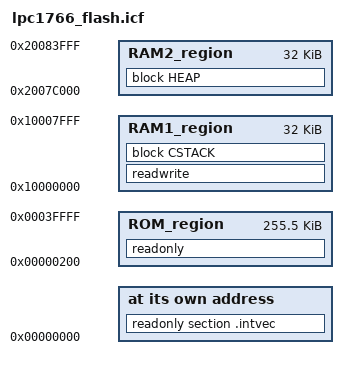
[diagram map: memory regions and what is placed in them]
/*###ICF### Section handled by ICF editor, don't touch! ****/
/*-Editor annotation file-*/
/* IcfEditorFile="$TOOLKIT_DIR$\config\ide\IcfEditor\cortex_v1_0.xml" */
/*-Specials-*/
define symbol __ICFEDIT_intvec_start__ = 0x00000000;
/*-Memory Regions-*/
define symbol __ICFEDIT_region_ROM_start__ = 0x00000200;
define symbol __ICFEDIT_region_ROM_end__   = 0x0003FFFF;
define symbol __ICFEDIT_region_RAM_start__ = 0x10000000;
define symbol __ICFEDIT_region_RAM_end__   = 0x10007FFF;
/*-Sizes-*/
define symbol __ICFEDIT_size_cstack__ = 0x400;
define symbol __ICFEDIT_size_heap__   = 0x8000;
/**** End of ICF editor section. ###ICF###*/

define symbol __ICFEDIT_region_RAM2_start__ = 0x2007C000;
define symbol __ICFEDIT_region_RAM2_end__   = 0x20083FFF;

define memory mem with size = 4G;
define region ROM_region   = mem:[from __ICFEDIT_region_ROM_start__   to __ICFEDIT_region_ROM_end__];
define region RAM1_region  = mem:[from __ICFEDIT_region_RAM_start__   to __ICFEDIT_region_RAM_end__];
define region RAM2_region  = mem:[from __ICFEDIT_region_RAM2_start__  to __ICFEDIT_region_RAM2_end__];

define block CSTACK    with alignment = 8, size = __ICFEDIT_size_cstack__   { };
define block HEAP      with alignment = 8, size = __ICFEDIT_size_heap__     { };

initialize by copy { readwrite };
do not initialize  { section .noinit };

place at address mem:__ICFEDIT_intvec_start__ { readonly section .intvec };

place in ROM_region   { readonly };
place in RAM1_region  { readwrite, block CSTACK };
place in RAM2_region  { block HEAP };
